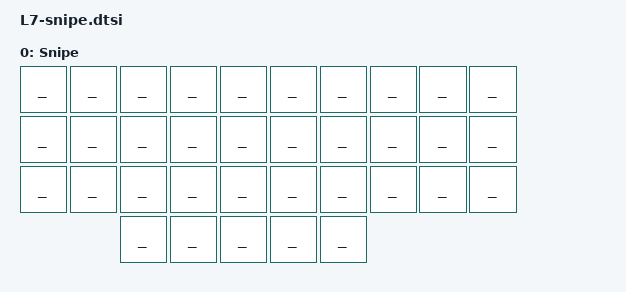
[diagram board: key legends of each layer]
/**
 *
 */

/ {
  keymap {
    compatible = "zmk,keymap";

	snipe_layer {
		label = "Snipe";
		bindings = <
//	╭───────────────┬───────────────┬───────────────┬───────────────┬───────────────╮   ╭───────────────┬───────────────┬───────────────┬───────────────┬───────────────╮
	________		________    	________		________		________			________        ________     	________        ________        ________
//	├───────────────┼───────────────┼───────────────┼───────────────┼───────────────┤   ├───────────────├───────────────┼───────────────┼───────────────┼───────────────┤
	________		________    	________		________		________			________        ________     	________        ________      ________
//	├───────────────┼───────────────┼───────────────┼───────────────┼───────────────┤   ├───────────────├───────────────┼───────────────┼───────────────┼───────────────┤
	________		________    	________		________		________            ________        ________     	________        ________        ________ 
//	╰───────────────┴───────────────┼───────────────┼───────────────┼───────────────┤   ├───────────────├───────────────┼───────────────┼───────────────┴───────────────╯
	       							________		________        ________           	________		________
//                                                  ╰───────────────┴───────────────╯   ╰───────────────┴───────────────╯
			>;
		};
	};
};
